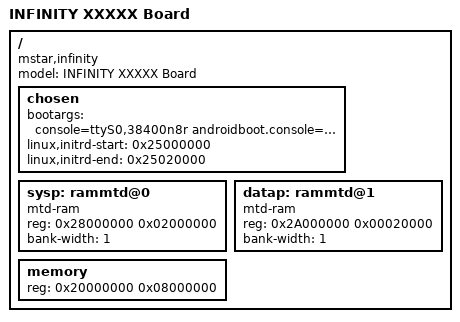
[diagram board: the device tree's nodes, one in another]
/*
 * Copyright (c) 2014 MundoReader S.L.
 * Author: Matthias Brugger <matthias.bgg@gmail.com>
 *
 * This program is free software; you can redistribute it and/or modify
 * it under the terms of the GNU General Public License as published by
 * the Free Software Foundation; either version 2 of the License, or
 * (at your option) any later version.
 *
 * This program is distributed in the hope that it will be useful,
 * but WITHOUT ANY WARRANTY; without even the implied warranty of
 * MERCHANTABILITY or FITNESS FOR A PARTICULAR PURPOSE.  See the
 * GNU General Public License for more details.
 */

/dts-v1/;
#include "infinity-zebu.dtsi"

/ {
	model = "INFINITY XXXXX Board";
	compatible = "mstar,infinity";
	

	chosen {
		bootargs = "console=ttyS0,38400n8r androidboot.console=ttyS0 root=/dev/ram rootwait sysp=squashfs:/dev/block/mtdblock0 datap=jffs2:/dev/block/mtdblock1";
//		bootargs = "console=ttyS0,38400n8r androidboot.console=ttyS0 root=/dev/ram rootwait";
		linux,initrd-start = <0x25000000>;
		linux,initrd-end =   <0x25020000>;
	};


    sysp:rammtd@0 {
        compatible = "mtd-ram";
//        reg= <0x26000000 0x02000000>;
        reg= <0x28000000 0x02000000>;
        bank-width = <1>;
    };
    
    /* Size of this partition must be identical to the size of data.jffs2 due to JFFS2 limitation */
    datap:rammtd@1 {
        compatible = "mtd-ram";
//        reg= <0x25F00000 0x00100000>;
        reg= <0x2A000000 0x00020000>;
        bank-width = <1>;
    };

	memory {
		reg = <0x20000000 0x08000000>;
	};
};
